# PIC32CM1216JH01032 register map
Vendor: Microchip Technology; Series: PIC32CMJH01; File version: 0
CPU: CM0+ r0p0, little endian, MPU, no FPU, VTOR, 2 interrupt priority bits, 32 interrupts
Registers are 32-bit, read-write, reset 0x0 unless marked. A register's access mark holds for its fields unless they carry their own. Offsets are from the block's base; [hi:lo] are bit positions; 'fields as' and 'values as' point back to an identical list.

## RSTC — Reset Controller
Base 0x40000C00
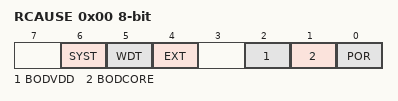
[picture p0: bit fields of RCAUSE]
0x00 RCAUSE 8-bit ro — Reset Cause
  [6] SYST — System Reset Request
  [5] WDT — Watchdog Reset
  [4] EXT — External Reset
  [2] BODVDD — Brown Out VDD Detector Reset
  [1] BODCORE — Brown Out CORE Detector Reset
  [0] POR — Power On Reset

## SUPC — Supply Controller
Base 0x40001800
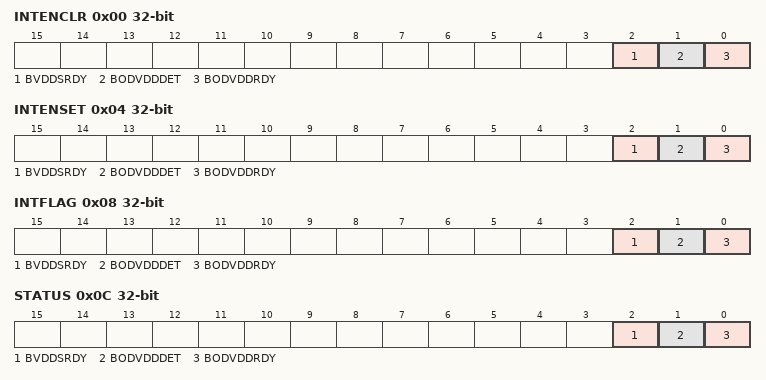
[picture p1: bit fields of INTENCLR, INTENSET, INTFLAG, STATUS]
0x00 INTENCLR write-1-clears — Interrupt Enable Clear
  [2] BVDDSRDY — BODVDD Synchronization Ready
  [1] BODVDDDET — BODVDD Detection
  [0] BODVDDRDY — BODVDD Ready
0x04 INTENSET write-1-sets — Interrupt Enable Set
  fields as INTENCLR
0x08 INTFLAG write-1-clears — Interrupt Flag Status and Clear
  fields as INTENCLR
0x0C STATUS ro — Power and Clocks Status
  fields as INTENCLR
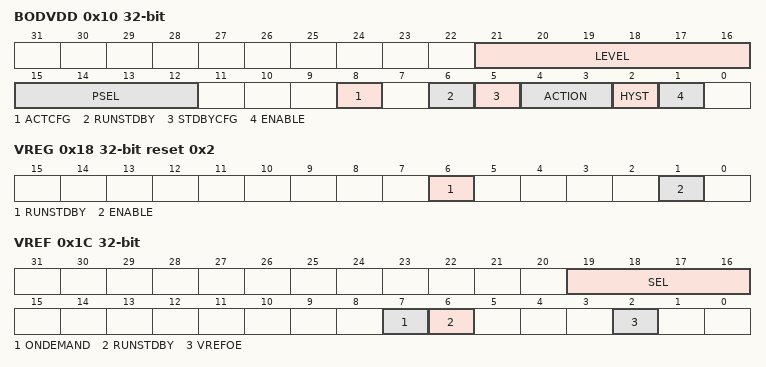
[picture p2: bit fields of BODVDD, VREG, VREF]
0x10 BODVDD — BODVDD Control
  [21:16] LEVEL — Threshold Level for VDD
  [15:12] PSEL — Prescaler Select
    0=DIV2 (Divide clock by 2); 1=DIV4 (Divide clock by 4); 2=DIV8 (Divide clock by 8); 3=DIV16 (Divide clock by 16); 4=DIV32 (Divide clock by 32); 5=DIV64 (Divide clock by 64); 6=DIV128 (Divide clock by 128); 7=DIV256 (Divide clock by 256); 8=DIV512 (Divide clock by 512); 9=DIV1024 (Divide clock by 1024); 10=DIV2048 (Divide clock by 2048); 11=DIV4096 (Divide clock by 4096); 12=DIV8192 (Divide clock by 8192); 13=DIV16384 (Divide clock by 16384); 14=DIV32768 (Divide clock by 32768); 15=DIV65536 (Divide clock by 65536)
  [8] ACTCFG — Configuration in Active mode
  [6] RUNSTDBY — Run during Standby
  [5] STDBYCFG — Configuration in Standby mode
  [4:3] ACTION — Action when Threshold Crossed
    0=NONE (No action); 1=RESET (The BODVDD generates a reset); 2=INT (The BODVDD generates an interrupt)
  [2] HYST — Hysteresis Enable
  [1] ENABLE
0x18 VREG reset 0x2 — VREG Control
  [6] RUNSTDBY — Run during Standby
  [1] ENABLE
0x1C VREF — VREF Control
  [19:16] SEL — Voltage Reference Selection
    0=1V024 (1.024V voltage reference typical value); 2=2V048 (2.048V voltage reference typical value); 3=4V096 (4.096V voltage reference typical value)
  [7] ONDEMAND — On Demand Control
  [6] RUNSTDBY — Run during Standby
  [2] VREFOE — Voltage Reference Output Enable

## SysTick — System timer
Base 0xE000E010
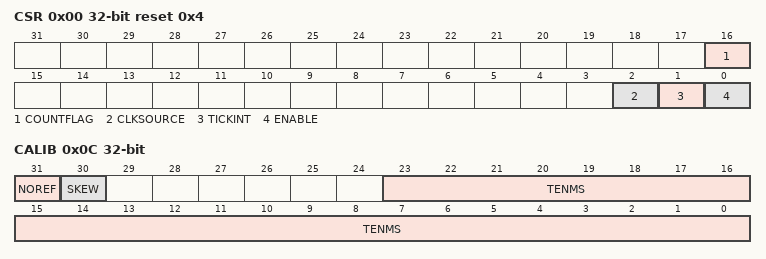
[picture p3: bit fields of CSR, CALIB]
0x00 CSR reset 0x4 — SysTick Control and Status Register
  [16] COUNTFLAG — Timer counted to 0 since last read of register
  [2] CLKSOURCE — Clock Source 0=external, 1=processor
    0=External clock; 1=Processor clock
  [1] TICKINT — SysTick Exception Request Enable
    0=Counting down to 0 does not assert the SysTick exception request; 1=Counting down to 0 asserts the SysTick exception request
  [0] ENABLE — SysTick Counter Enable
    0=Counter disabled; 1=Counter enabled
0x04 RVR — SysTick Reload Value Register
  [23:0] RELOAD — Value to load into the SysTick Current Value Register when the counter reaches 0
0x08 CVR — SysTick Current Value Register
  [23:0] CURRENT — Current value at the time the register is accessed
0x0C CALIB ro — SysTick Calibration Value Register
  [31] NOREF — No Separate Reference Clock
    0=The reference clock is provided; 1=The reference clock is not provided
  [30] SKEW — TENMS is rounded from non-integer ratio
    0=10ms calibration value is exact; 1=10ms calibration value is inexact, because of the clock frequency
  [23:0] TENMS — Reload value to use for 10ms timing

## SystemControl — System Control Registers
Base 0xE000E000
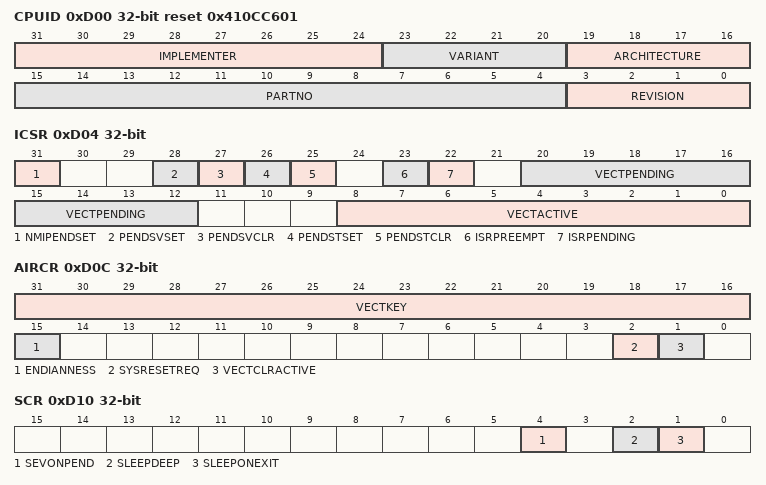
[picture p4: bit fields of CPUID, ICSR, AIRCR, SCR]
0xD00 CPUID ro reset 0x410CC601 — CPUID Base Register
  [31:24] IMPLEMENTER — Implementer code, ARM=0x41
  [23:20] VARIANT — Major revision number
  [19:16] ARCHITECTURE — Processor Architecture, 0xC=ARMv6-M
  [15:4] PARTNO — Processor Part Number, 0xC60=Cortex-M0+
  [3:0] REVISION — Minor revision number
0xD04 ICSR — Interrupt Control and State Register
  [31] NMIPENDSET — NMI set-pending bit
    0=Write: no effect; read: NMI exception is not pending; 1=Write: changes NMI exception state to pending; read: NMI exception is pending
  [28] PENDSVSET — PendSV set-pending bit
    0=Write: no effect; read: PendSV exception is not pending; 1=Write: changes PendSV exception state to pending; read: PendSV exception is pending
  [27] PENDSVCLR — PendSV clear-pending bit
    0=No effect; 1=Removes the pending state from the PendSV exception
  [26] PENDSTSET — SysTick exception set-pending bit
    0=Write: no effect; read: SysTick exception is not pending; 1=Write: changes SysTick exception state to pending; read: SysTick exception is pending
  [25] PENDSTCLR — SysTick exception clear-pending bit
    0=No effect; 1=Removes the pending state from the SysTick exception
  [23] ISRPREEMPT — Debug: Pending exception serviced on exit from debug halt
  [22] ISRPENDING — Debug: NVIC interrupt pending
  [20:12] VECTPENDING — Exception number of the highest priority pending enabled exception
  [8:0] VECTACTIVE — Debug: Exception number of currently executing exception, or 0 if thread mode
0xD08 VTOR — Vector Table Offset Register
  [31:7] TBLOFF — Vector table base offset
0xD0C AIRCR — Application Interrupt and Reset Control Register
  [31:16] VECTKEY — Register key (0x05FA)
  [15] ENDIANNESS — Data Endianness, 0=little, 1=big
    0=Little-endian; 1=Big-endian
  [2] SYSRESETREQ — System Reset Request
    0=No system reset request; 1=Asserts a signal to the outer system that requests a reset
  [1] VECTCLRACTIVE — Debug: Clear state information
0xD10 SCR — System Control Register
  [4] SEVONPEND — Send Event on Pending bit
    0=Only enabled interrupts or events can wakeup the processor, disabled interrupts are excluded; 1=Enabled events and all interrupts, including disabled interrupts, can wakeup the processor
  [2] SLEEPDEEP — Uses Deep Sleep as low power mode
    0=Sleep; 1=Deep sleep
  [1] SLEEPONEXIT — Sleep-On-Exit when exiting Handler mode
    0=O not sleep when returning to Thread mode; 1=Enter sleep, or deep sleep, on return from an ISR
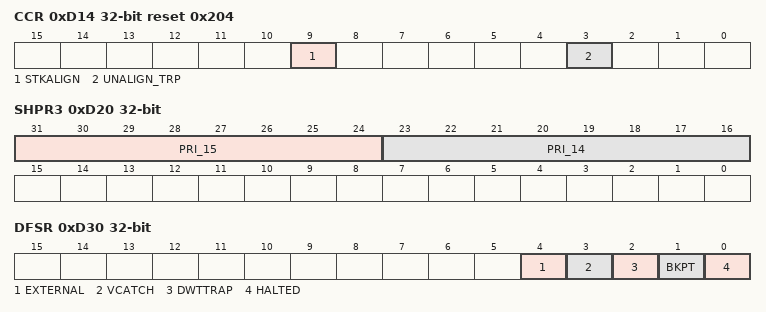
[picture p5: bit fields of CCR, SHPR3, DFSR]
0xD14 CCR ro reset 0x204 — Configuration and Control Register
  [9] STKALIGN — Stack 8-byte aligned on exception entry
    0=4-byte aligned; 1=8-byte aligned
  [3] UNALIGN_TRP — Unaligned accesses generates a Hard Fault
    0=Do not trap unaligned halfword and word accesses; 1=Trap unaligned halfword and word accesses
0xD1C SHPR2 — System Handler Priority Register 2
  [31:24] PRI_11 — Priority of system handler 11, SVCall
0xD20 SHPR3 — System Handler Priority Register 3
  [31:24] PRI_15 — Priority of system handler 15, SysTick exception
  [23:16] PRI_14 — Priority of system handler 14, PendSV
0xD24 SHCSR — System Handler Control and State Register
  [15] SVCALLPENDED
0xD30 DFSR — Debug Fault Status Register
  [4] EXTERNAL — EDBGRQ debug event
  [3] VCATCH — Vector catch debug event
  [2] DWTTRAP — DWT debug event
  [1] BKPT — Breakpoint debug event
  [0] HALTED — Halt request debug event active

## WDT — Watchdog Timer
Base 0x40002000
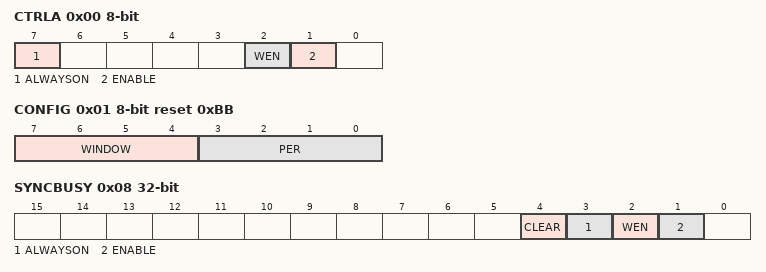
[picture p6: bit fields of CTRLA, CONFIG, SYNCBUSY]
0x00 CTRLA 8-bit — Control
  [7] ALWAYSON
  [2] WEN — Watchdog Timer Window Mode Enable
  [1] ENABLE
0x01 CONFIG 8-bit reset 0xBB — Configuration
  [7:4] WINDOW — Window Mode Time-Out Period
    0=CYC8 (8 clock cycles); 1=CYC16 (16 clock cycles); 2=CYC32 (32 clock cycles); 3=CYC64 (64 clock cycles); 4=CYC128 (128 clock cycles); 5=CYC256 (256 clock cycles); 6=CYC512 (512 clock cycles); 7=CYC1024 (1024 clock cycles); 8=CYC2048 (2048 clock cycles); 9=CYC4096 (4096 clock cycles); 10=CYC8192 (8192 clock cycles); 11=CYC16384 (16384 clock cycles)
  [3:0] PER — Time-Out Period
    values as WINDOW
0x02 EWCTRL 8-bit reset 0xB — Early Warning Interrupt Control
  [3:0] EWOFFSET — Early Warning Interrupt Time Offset
    0=CYC8 (8 clock cycles); 1=CYC16 (16 clock cycles); 2=CYC32 (32 clock cycles); 3=CYC64 (64 clock cycles); 4=CYC128 (128 clock cycles); 5=CYC256 (256 clock cycles); 6=CYC512 (512 clock cycles); 7=CYC1024 (1024 clock cycles); 8=CYC2048 (2048 clock cycles); 9=CYC4096 (4096 clock cycles); 10=CYC8192 (8192 clock cycles)
0x04 INTENCLR 8-bit write-1-clears — Interrupt Enable Clear
  [0] EW — Early Warning Interrupt Enable
0x05 INTENSET 8-bit write-1-sets — Interrupt Enable Set
  [0] EW — Early Warning Interrupt Enable
0x06 INTFLAG 8-bit write-1-clears — Interrupt Flag Status and Clear
  [0] EW — Early Warning
0x08 SYNCBUSY ro — Synchronization Busy
  [4] CLEAR — Clear Synchronization Busy
  [3] ALWAYSON — Always-On Synchronization Busy
  [2] WEN — Window Enable Synchronization Busy
  [1] ENABLE — Enable Synchronization Busy
0x0C CLEAR 8-bit wo
  [7:0] CLEAR — Watchdog Clear
    165=KEY (Clear Key)
